# hif_secure register map
Vendor: Texas Instruments
Peripheral module from a debugger description file (folder CC35X1E).
Registers are 32-bit, read-only, reset 0x0 unless marked. A register's access mark holds for its fields unless they carry their own. Offsets are as the file gives them; lines under a group give offsets from that group; [hi:lo] are bit positions; {n}, {i} and the like mark numbered series; 'fields as' and 'values as' point back to an identical list; <NAME> marks a mode.

## hif_secure
0x00 ic_wr_fifo_word wo — INTERCONNECT WRITE FIFO Host interface FIFO
  [31:0] WORD — WORD write opt IC to NAB write word
0x10 ic_rd_fifo_word reset 0xEEEEEEEE — INTERCONNECT READ FIFO Host interface FIFO
  [31:0] WORD — WORD read clear NAB to IC read word
0x24 hif_mode access per field — MODE HIF Mode Configuration
  [1:0] CFG rw — CONFIG "00" - Direct Access WR "01" - DMA WR "10" - Direct Access RD "11" - DMA RD
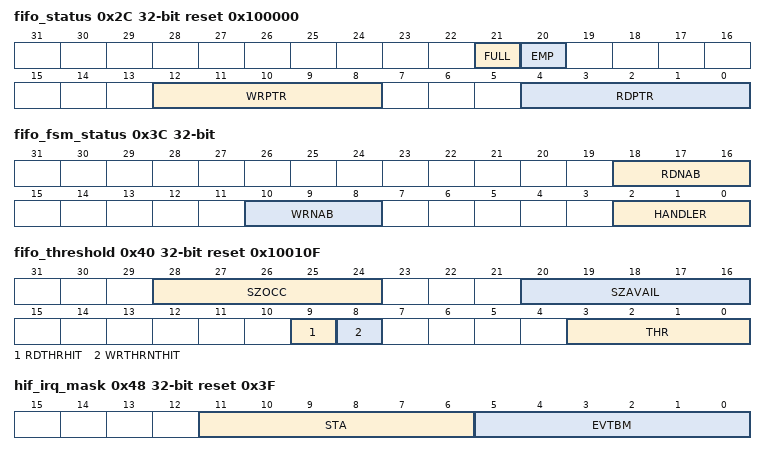
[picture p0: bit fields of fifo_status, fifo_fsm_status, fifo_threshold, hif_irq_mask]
0x2C fifo_status reset 0x100000 — HIF FIFO Status
  [21] FULL
  [20] EMP — EMPTY
  [12:8] WRPTR — WRITE POINTER
  [4:0] RDPTR — READ POINTER
0x30 fifo_underflow — UNDERFLOW clear on read. H/W latch underflow and s/w clears it by reading.
  [0] STA — STATUS read clear FIFO Underflow - RD when FIFO is empty.
0x34 fifo_overflow — OVERFLOW clear on read. H/W latch overflow and s/w clears it by reading.
  [0] STA — STATUS read clear FIFO Overflow - WR when FIFO is full.
0x38 rst_fifo_pulse access per field — RESET HIF FIFO set RESET
  [0] FIFO wo — FIFO write clear Setting this bit clears the FIFO Controls.
0x3C fifo_fsm_status — FSM STATUS
  [18:16] RDNAB — READ NAB
  [10:8] WRNAB — WRITE NAB
  [2:0] HANDLER — HANDLER IDLE = 3'b000 DMA_BL_WR = 3'b101 DMA_HOLD_WR = 3'b110 DIRECT_ACCESS_WR = 3'b111 NAB_WR = 3'b001 DMA_BL_RD = 3'b010 DIRECT_ACCESS_RD = 3'b011 ;
0x40 fifo_threshold access per field reset 0x10010F — HIF FIFO Threshold Status
  [28:24] SZOCC ro — SIZE OCCUPIED indication of how many words have been written to FIFO 0 - nothing was written 1 - 1 word have been written ... 16 - 16 words have been written
  [20:16] SZAVAIL ro — SIZE AVAILABLE indication of free space left at FIFO 0 - FIFO full 1 - 1 word can be written ... 16 - 16 words can be written
  [9] RDTHRHIT ro — READ THRESHOLD HIT indication if the read threshold hit
  [8] WRTHRNTHIT ro — WRITE THRESHOLD NOT HIT indication if the write threshold not hit
  [3:0] THR rw — THRESHOLD Sets the HIF threshold: for TX (DMA to NAB)- 0 - if there is room for 1 word the req to DMA will be send ... 15 - if there is room for 16 words the req to DMA will be send for RX (NAB to DMA)- 0 - if FIFO is occupied by at lest 1 word, the req to DMA will be send ... 15 - if FIFO is occupied by at lest 16 word, the req to DMA will be send
0x44 hif_irq_read reset 0x1 — IRQ
  [5:0] RIS — RIS read clear bit[0] - empty bit[1] - full bit[2] - underflow bit[3] - overflow bit[4] - not empty with direct access read bit[5] - nab data receive done
0x48 hif_irq_mask access per field reset 0x3F — IRQ MASK Config
  [11:6] STA ro — STATUS bit[0] - empty bit[1] - full bit[2] - underflow bit[3] - overflow bit[4] - not empty with direct access read bit[5] - nab data receive done
  [5:0] EVTBM rw — EVENT BIT MASK '1' - Mask '0' - Do Not Mask bit[0] - empty bit[1] - full bit[2] - underflow bit[3] - overflow bit[4] - not empty with direct access read bit[5] - nab data receive done
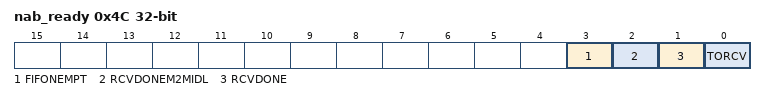
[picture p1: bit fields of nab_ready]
0x4C nab_ready — NAB READY HIF Mode Configuration
  [3] FIFONEMPT — NAB HOST FIFO NOT EMPTY indication when NAB FIFO not empty
  [2] RCVDONEM2MIDL — RECEIVE DONE AND M2M IDLE indication when NAB data recieve done and M2M FSM IDLE
  [1] RCVDONE — RECEIVE DONE indication when NAB data recieve done
  [0] TORCV — TO RECEIVE indication when NAB is ready to receive data
0x50 hif_core_timestamp — CORE HIF Mode Configuration
  [31:0] TMSTMP — TIMESTAMP
0x54 rx_status_aon — RX AON
  [31:0] STA — STATUS read clear This is not a regular clear-on-read register. A fresh status value from Rx sub system is being latch upon reading the register. The objective is for the device to have the last value the host has read
0x58 rx_status_latch
  [31:0] VAL — VALUE Reflects the Rx status word current value (dynamic Read). and automatically latch the value in RX_STATUS_LATCH_LATCHED. Usage: SDIO Wrapper reads this location and send the read value toward the host. For bit field description refer to RX_STATUS_LATCH. This register is valid only in BSD_BYPASS=1 (Osprey).
0x5C nab_hint_status_masked — NAB HINT STATUS
  [31:0] BMVAL — BIT MASK VALUE Host interrupt status read register. non-intrusive read. Post mask (masked).
0x60 nab_hint_mask — NAB
  [31:0] BMVAL — BIT MASK VALUE Read mask bitmap. Mask bit legend: '0' - do not mask the interrupt. '1' - Mask the related interrupt.
0x64 nab_hint_mask_set wo — HINT BIT MASK
  [31:0] VAL — VALUE write clear Host interrupt mask register set Writing to this register will set to '1' the related interrupt mask bit. Mask bit legend: '0' - do not mask the interrupt. '1' - Mask the related interrupt.
0x68 nab_hint_mask_clr wo — HINT BIT MASK CLEAR
  [31:0] VAL — VALUE write clear Host interrupt mask register clear Writing to this register will clear the related interrupt mask bit. Mask bit legend: '0' - do not mask the interrupt. '1' - Mask the related interrupt.
0x6C nab_hint_status_clr_on_rd — HINT STATUS CLEAR
  [31:0] STA — STATUS read clear Host interrupt status clear-on-read register Clears all bits of upon read. Usage: host reads the IRQ register which is automatically getting cleared by H/W Osprey Note: The endianness correction and word-size correction are done in SDIO(WSPI) H/W.
0x70 nab_hint_set wo — NAB HINT
  [31:0] SET — SET write clear register Host interrupt set register
0x74 nab_hint_clr wo — NAB HINT CLEAR
  [31:0] SET — SET write clear register Host interrupt clear register
